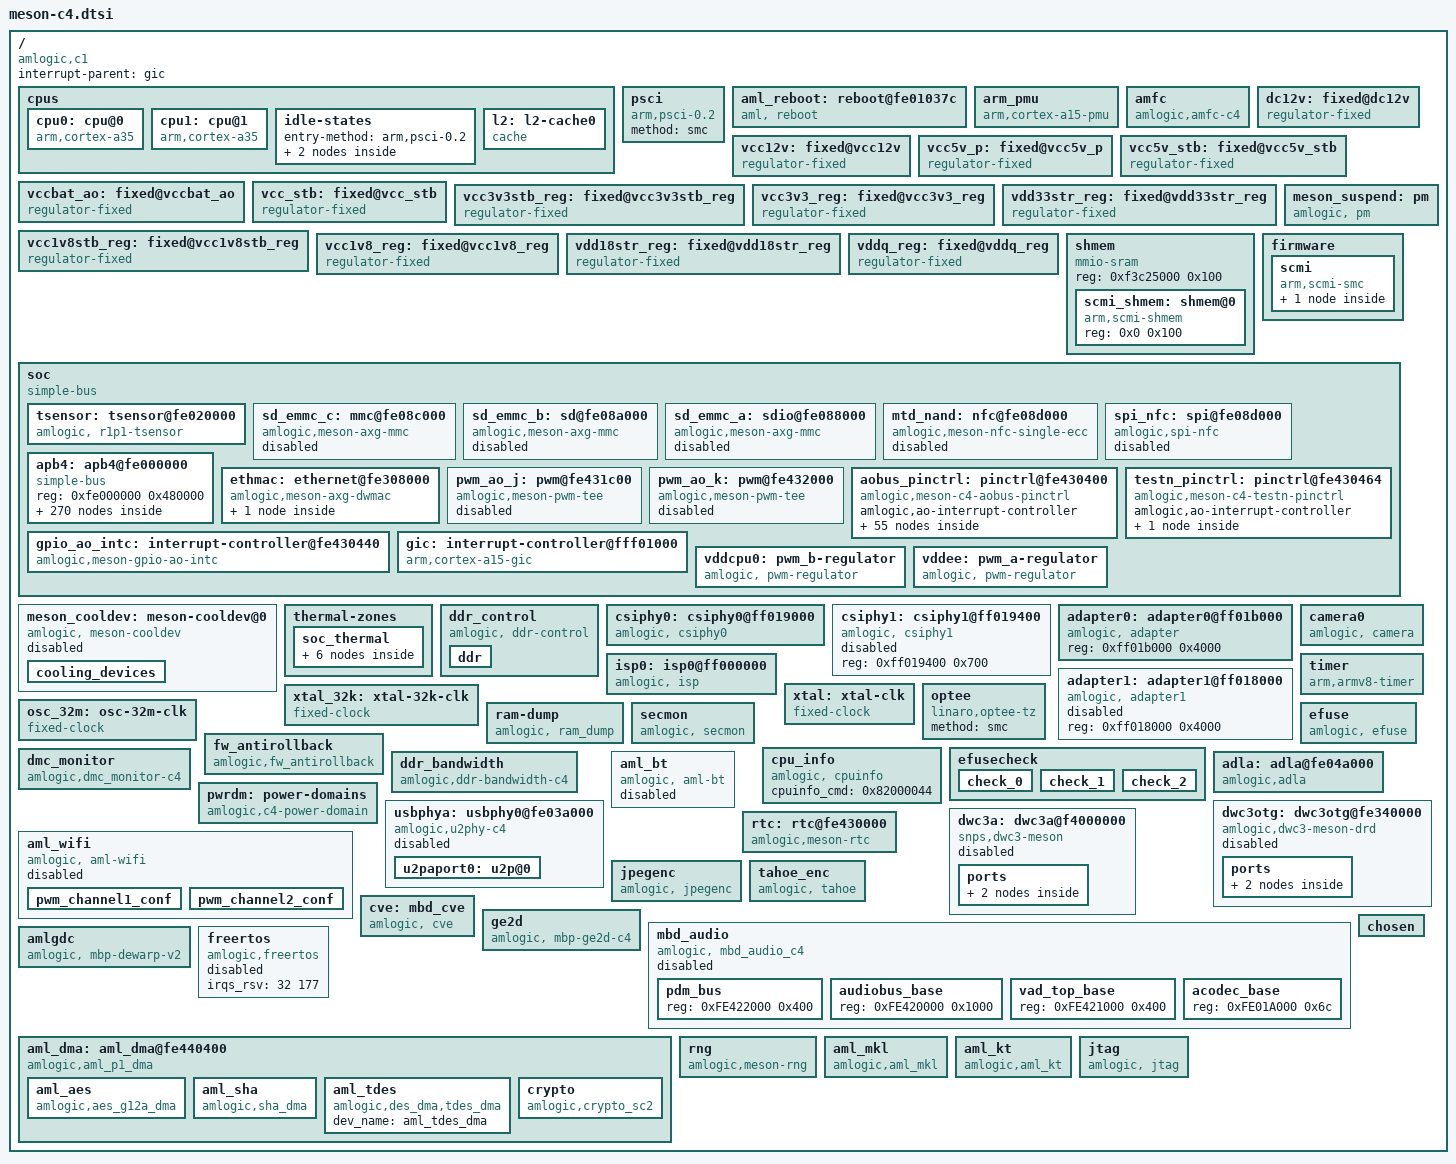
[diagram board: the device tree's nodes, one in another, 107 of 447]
// SPDX-License-Identifier: (GPL-2.0+ OR MIT)
/*
 * Copyright (c) 2019 Amlogic, Inc. All rights reserved.
 */

#include <dt-bindings/interrupt-controller/irq.h>
#include <dt-bindings/interrupt-controller/arm-gic.h>
#include <dt-bindings/clock/amlogic,c4-clkc.h>
#include <dt-bindings/clock/amlogic,c4-scmi-clks.h>
#include <dt-bindings/gpio/gpio.h>
#include <dt-bindings/gpio/meson-c4-gpio.h>
#include <dt-bindings/pwm/pwm.h>
#include <dt-bindings/pwm/meson.h>
#include <dt-bindings/reset/amlogic,meson-c4-reset.h>
#include <dt-bindings/input/input.h>
#include <dt-bindings/input/meson_ir.h>
#include <dt-bindings/iio/adc/amlogic-saradc.h>
#include "meson-ir-map.dtsi"
#include <dt-bindings/power/c4-pd.h>
#include <dt-bindings/mailbox/amlogic,mbox.h>
#include <dt-bindings/thermal/thermal.h>
#include <dt-bindings/thermal/ddr-params.h>
#include <dt-bindings/power/meson-pm.h>

/ {
	compatible = "amlogic,c1";

	interrupt-parent = <&gic>;
	#address-cells = <1>;
	#size-cells = <1>;

	cpus {
		#address-cells = <1>;
		#size-cells = <0>;

		cpu0: cpu@0 {
			device_type = "cpu";
			compatible = "arm,cortex-a35";
			reg = <0x0>;
			enable-method = "psci";
			cpu-idle-states = <&CPU_SLEEP_0>;
			next-level-cache = <&l2>;
			#cooling-cells = <2>;
			dynamic-power-coefficient = <70>;
		};

		cpu1: cpu@1 {
			device_type = "cpu";
			compatible = "arm,cortex-a35";
			reg = <0x1>;
			enable-method = "psci";
			cpu-idle-states = <&CPU_SLEEP_0>;
			next-level-cache = <&l2>;
			#cooling-cells = <2>;
			dynamic-power-coefficient = <70>;
		};
		idle-states {
			entry-method = "arm,psci-0.2";
			CPU_SLEEP_0: cpu-sleep-0 {
					compatible = "arm,idle-state";
					arm,psci-suspend-param = <0x0010000>;
					local-timer-stop;
					entry-latency-us = <3000>;
					exit-latency-us = <3000>;
					min-residency-us = <8000>;
			};
			SYSTEM_SLEEP_0: system-sleep-0 {
					compatible = "arm,idle-state";
					arm,psci-suspend-param = <0x0000000>;
					entry-latency-us = <0x3fffffff>;
					exit-latency-us = <0x40000000>;
					min-residency-us = <0xffffffff>;
			};
		};

		l2: l2-cache0 {
			compatible = "cache";
		};
	};

	psci {
		compatible = "arm,psci-0.2";
		method = "smc";
	};

	aml_reboot: reboot@fe01037c {
		compatible = "aml, reboot";
		sys_reset = <0x84000009>;
		sys_poweroff = <0x84000008>;
		extend_reboot_reason; /* Support up to 128 reboot reasons*/
		reg = <0xfe01037c 0x4>; /* SEC_AO_SEC_SD_CFG15 */
		status = "okay";
	};

	arm_pmu {
		compatible = "arm,cortex-a15-pmu";
		/* clusterb-enabled; */
		private-interrupts;
		interrupts = <GIC_SPI 233 IRQ_TYPE_LEVEL_HIGH>,
			     <GIC_SPI 234 IRQ_TYPE_LEVEL_HIGH>;
	};

	amfc {
		compatible = "amlogic,amfc-c4";
		status = "okay";
		/* registers and clk */
		reg = <0xfe024000 0x200
		       0xfe000000 0x400>;
		interrupts = <0 90 IRQ_TYPE_EDGE_RISING
			      0 91 IRQ_TYPE_EDGE_RISING>;
		power-domains = <&pwrdm PDID_C4_AMFC>;
		interrupt-names = "amfc0", "amfc1";
		clocks = <&clkc CLKID_AMFC>;
		assigned-clocks = <&clkc CLKID_AMFC>;
		assigned-clock-rates = <666666666>;
	};

	dc12v: fixed@dc12v {
		compatible = "regulator-fixed";
		regulator-name = "DC12V";
		regulator-min-microvolt = <12000000>;
		regulator-max-microvolt = <12000000>;
		regulator-boot-on;
		regulator-always-on;
	};

	vcc12v: fixed@vcc12v {
		compatible = "regulator-fixed";
		vin-supply = <&dc12v>;
		regulator-name = "VCC12V";
		regulator-min-microvolt = <12000000>;
		regulator-max-microvolt = <12000000>;
		regulator-boot-on;
		regulator-always-on;
	};

	vcc5v_p: fixed@vcc5v_p {
		compatible = "regulator-fixed";
		vin-supply = <&dc12v>;
		regulator-name = "VCC5V_P";
		regulator-min-microvolt = <5000000>;
		regulator-max-microvolt = <5000000>;
		regulator-boot-on;
		regulator-always-on;
	};

	vcc5v_stb: fixed@vcc5v_stb {
		compatible = "regulator-fixed";
		vin-supply = <&dc12v>;
		regulator-name = "VCC5V_STB";
		regulator-min-microvolt = <5000000>;
		regulator-max-microvolt = <5000000>;
		regulator-boot-on;
		regulator-always-on;
	};

	vccbat_ao: fixed@vccbat_ao {
		compatible = "regulator-fixed";
		vin-supply = <&vcc5v_stb>;
		regulator-name = "VCCBAT_AO";
		regulator-min-microvolt = <3300000>;
		regulator-max-microvolt = <3300000>;
		regulator-boot-on;
		regulator-always-on;
	};

	vcc_stb: fixed@vcc_stb {
		compatible = "regulator-fixed";
		vin-supply = <&vccbat_ao>;
		regulator-name = "VCC_STB";
		regulator-min-microvolt = <3300000>;
		regulator-max-microvolt = <3300000>;
		regulator-boot-on;
		regulator-always-on;
	};

	vcc3v3stb_reg: fixed@vcc3v3stb_reg{
		compatible = "regulator-fixed";
		vin-supply = <&vcc_stb>;
		regulator-name = "VCC3V3STB";
		regulator-min-microvolt = <3300000>;
		regulator-max-microvolt = <3300000>;
		regulator-boot-on;
		regulator-always-on;
	};

	vcc3v3_reg: fixed@vcc3v3_reg{
		compatible = "regulator-fixed";
		vin-supply = <&vcc3v3stb_reg>;
		regulator-name = "VCC3V3";
		regulator-min-microvolt = <3300000>;
		regulator-max-microvolt = <3300000>;
		regulator-boot-on;
		regulator-always-on;
	};

	vdd33str_reg: fixed@vdd33str_reg{
		compatible = "regulator-fixed";
		vin-supply = <&vcc3v3stb_reg>;
		regulator-name = "VDD33_STR";
		regulator-min-microvolt = <3300000>;
		regulator-max-microvolt = <3300000>;
		pinctrl-names = "default";
		gpio = <&ao_gpio GPIOAO_1 GPIO_ACTIVE_HIGH>;
		startup-delay-us = <7000>;
		enable-active-high;
		regulator-boot-on;
		regulator-always-on;
	};

	vcc1v8stb_reg: fixed@vcc1v8stb_reg{
		compatible = "regulator-fixed";
		vin-supply = <&vcc_stb>;
		regulator-name = "VCC1V8STB";
		regulator-min-microvolt = <1800000>;
		regulator-max-microvolt = <1800000>;
		regulator-boot-on;
		regulator-always-on;
	};

	vcc1v8_reg: fixed@vcc1v8_reg{
		compatible = "regulator-fixed";
		vin-supply = <&vcc1v8stb_reg>;
		regulator-name = "VCC1V8";
		regulator-min-microvolt = <1800000>;
		regulator-max-microvolt = <1800000>;
		regulator-boot-on;
		regulator-always-on;
	};

	vdd18str_reg: fixed@vdd18str_reg{
		compatible = "regulator-fixed";
		vin-supply = <&vcc1v8stb_reg>;
		regulator-name = "VDD18_STR";
		regulator-min-microvolt = <1800000>;
		regulator-max-microvolt = <1800000>;
		pinctrl-names = "default";
		gpio = <&ao_gpio GPIOAO_1 GPIO_ACTIVE_HIGH>;
		startup-delay-us = <7000>;
		enable-active-high;
		regulator-boot-on;
		regulator-always-on;
	};

	vddq_reg: fixed@vddq_reg {
		compatible = "regulator-fixed";
		vin-supply = <&vcc_stb>;
		regulator-name = "VDDQ";
		regulator-min-microvolt = <1200000>;
		regulator-max-microvolt = <1200000>;
		pinctrl-names = "default";
		gpio = <&ao_gpio GPIOAO_1 GPIO_ACTIVE_HIGH>;
		startup-delay-us = <7000>;
		enable-active-high;
		regulator-boot-on;
		regulator-always-on;
	};

	meson_suspend:pm {
		compatible = "amlogic, pm";
		status = "okay";
		device_name = "aml_pm";
		extend_resume_reason;
		reg = <0xfe010288 0x4>, /*SYSCTRL_STATUS_REG2*/
			<0xfe43245c 0x4>; /*SYSCTRL_STICKY_REG7*/
		deep_mode = <SYSTEM_SUSPEND_EE_PWR_DOWN>;
		/*deep_mode supports custom configuration */
		// deep_mode = <(DEFINE(SENSOR, OFF) | DEFINE(LCD, ON) |DEFINE(DDR, SELFREFRESH))>;
	};

	shmem {
		compatible = "mmio-sram";
		reg = <0xf3c25000 0x100>;
		#address-cells = <1>;
		#size-cells = <1>;
		ranges = <0x0 0xf3c25000 0x100>;

		scmi_shmem: shmem@0 {
			compatible = "arm,scmi-shmem";
			reg = <0x0 0x100>;
		};
	};

	firmware {
		scmi: scmi {
			compatible = "arm,scmi-smc";
			arm,smc-id = <0x820000C1>;
			shmem = <&scmi_shmem>;
			#address-cells = <1>;
			#size-cells = <0>;

			scmi_clk: protocol@14 {
				reg = <0x14>;
				#clock-cells = <1>;
			};
		};
	};

	soc {
		compatible = "simple-bus";
		#address-cells = <1>;
		#size-cells = <1>;
		ranges;

		tsensor: tsensor@fe020000 {
			compatible = "amlogic, r1p1-tsensor";
			status = "okay";
			reg = <0xfe020000 0x50>;
			tsensor_id = <1>;
			cal_type = <0x11>;
			cal_coeff = <324 424 3159 9411>;
			rtemp = <110000>;
			interrupts = <GIC_SPI 30 IRQ_TYPE_LEVEL_HIGH>;
			clocks = <&clkc CLKID_TS>;
			clock-names = "ts_comp";
			#thermal-sensor-cells = <1>;
			reset-names = "ts_rst";
			resets = <&reset RESET_TS_PLL>;
		};

		sd_emmc_c: mmc@fe08c000 {
			compatible = "amlogic,meson-axg-mmc";
			reg = <0xfe08c000 0x800>,
			      <0xfe00016c 0x4>,
			      <0xfe004000 0x4>;
			interrupts = <GIC_SPI 178 IRQ_TYPE_EDGE_RISING>;
			status = "disabled";
			clocks = <&clkc CLKID_SYS_SD_EMMC_C>,
				 <&clkc CLKID_SD_EMMC_C_MUX>,
				 <&clkc CLKID_SD_EMMC_C>,
				 <&scmi_clk CLKID_OSC>,
				 <&clkc CLKID_GP0_PLL>;
			clock-names = "core", "mux0", "mux1", "clkin0", "clkin1";
			card_type = <1>;
			mmc_debug_flag;
			src_clk_rate = <1152000000>;
			tx_delay = <0x11>;
			full-pwr-cycle;
			no-sd;
			no-sdio;
			// resets = <&reset RESET_SD_EMMC_C>;
		};

		sd_emmc_b: sd@fe08a000 {
			compatible = "amlogic,meson-axg-mmc";
			reg = <0xfe08a000 0x800>,
			      <0xfe000168 0x4>,
			      <0xfe004024 0x4>;
			interrupts = <GIC_SPI 177 IRQ_TYPE_EDGE_RISING>;
			status = "disabled";
			clocks = <&clkc CLKID_SYS_SD_EMMC_B>,
				 <&clkc CLKID_SD_EMMC_B_MUX>,
				 <&clkc CLKID_SD_EMMC_B>,
				 <&scmi_clk CLKID_OSC>,
				 <&clkc CLKID_FCLK_DIV2>;
			clock-names = "core", "mux0", "mux1",
					"clkin0", "clkin1";
			card_type = <5>;
			mmc_debug_flag;
			no-mmc;
			no-sdio;
			// resets = <&reset RESET_SD_EMMC_B>;
		};

		sd_emmc_a: sdio@fe088000 {
			compatible = "amlogic,meson-axg-mmc";
			reg = <0xfe088000 0x800>,
			      <0xfe000168 0x4>,
			      <0xfe00400c 0x4>;
			status = "disabled";
			interrupts = <GIC_SPI 176 IRQ_TYPE_EDGE_RISING>;
			clocks = <&clkc CLKID_SYS_SD_EMMC_A>,
				<&clkc CLKID_SD_EMMC_A_MUX>,
				<&clkc CLKID_SD_EMMC_A>,
				<&scmi_clk CLKID_OSC>,
				<&clkc CLKID_FCLK_DIV2>;
				clock-names = "core", "mux0", "mux1", "clkin0", "clkin1";
			card_type = <3>;
			mmc_debug_flag;
			auto-clock-sdio;
			cap-sdio-irq;
			keep-power-in-suspend;
			no-mmc;
			no-sd;
			// resets = <&reset RESET_SD_EMMC_A>;
		};

		mtd_nand: nfc@fe08d000 {
			compatible = "amlogic,meson-nfc-single-ecc";
			status = "disabled";
			reg = <0xfe08d000 0x200>;
			interrupts = <GIC_SPI 87 IRQ_TYPE_EDGE_RISING>;

			clocks = <&clkc CLKID_SYS_SD_EMMC_C>,
					 <&clkc CLKID_FCLK_DIV2>;
			clock-names = "gate", "fdiv2pll";
			nand_clk_ctrl = <0xfe08c000>;
			//power-domains = <&pwrdm PDID_C3_EMMC>;
		};

		spi_nfc: spi@fe08d000 {
			compatible = "amlogic,spi-nfc";
			status = "disabled";
			reg = <0xfe08d000 0x200>,
				  <0xfe08c000 0xc>,
				  <0xfe010180 0x4>;
			clocks = <&clkc CLKID_SYS_SD_EMMC_C>,
					<&clkc CLKID_FCLK_DIV2>;
			clock-names = "gate", "fdiv2pll";
			nand_clk_ctrl = <0xfe08c000>;
			#address-cells = <1>;
			#size-cells = <0>;
		};

		apb4: apb4@fe000000 {
			compatible = "simple-bus";
			reg = <0xfe000000 0x480000>;
			#address-cells = <1>;
			#size-cells = <1>;
			ranges = <0x0 0xfe000000 0x480000>;

			clkc: clock-controller@0 {
				compatible = "amlogic,c4-clkc";
				#clock-cells = <1>;
				reg = <0x0    0x228>,
				      <0x8000 0x194>;
				reg-names = "basic", "pll";
				clocks = <&xtal>,
					 <&scmi_clk CLKID_OSC>,
					 <&scmi_clk CLKID_SYS_CLK>,
					 <&scmi_clk CLKID_AXI_CLK>,
					 <&scmi_clk CLKID_FIXED_PLL>;
				clock-names = "xtal",
					      "oscin",
					      "sys_clk",
					      "axi_clk",
					      "fixed_pll";
				status = "okay";
			};

			reset: reset-controller@2000 {
				compatible = "amlogic,meson-sc2-reset";
				reg = <0x2000 0x98>;
				#reset-cells = <1>;
			};

			periphs_pinctrl: pinctrl@4000 {
				compatible = "amlogic,meson-c4-periphs-pinctrl";
				#address-cells = <1>;
				#size-cells = <1>;
				ranges;

				gpio: bank@4000 {
					reg = <0x4000 0x004c>,
					      <0x40c0 0x0240>;
					reg-names = "mux", "gpio";
					gpio-controller;
					#gpio-cells = <2>;
					gpio-ranges = <&periphs_pinctrl 0 0 55>;
				};
			};

			gpio_intc: interrupt-controller@4080 {
				compatible = "amlogic,meson-gpio-intc",
					      "amlogic,meson-c4-gpio-intc";
				reg = <0x4080 0x20>;
				interrupt-controller;
				#interrupt-cells = <2>;
				amlogic,channel-interrupts =
							<10 11 12 13 14 15 16 17 18 19 20 21>;
			};

			analog_pinctrl: pinctrl@43a0 {
				compatible = "amlogic,meson-c3-analog-pinctrl";
				#address-cells = <1>;
				#size-cells = <1>;
				ranges;

				gpio_analog: bank@43a0 {
					reg = <0x404c 0x008>,
					      <0x438c 0x030>;
					reg-names = "mux", "gpio";
					gpio-controller;
					#gpio-cells = <2>;
					gpio-ranges = <&analog_pinctrl 0 0 14>;
				};
			};

			meson_clk_msr@48000 {
				compatible = "amlogic,c4-clk-measure";
				reg = <0x48000 0x1c>;
			};

			spicc0: spi@50000 {
				compatible = "amlogic,meson-t6x-spicc-v2";
				reg = <0x50000 0x100>;
				interrupts = <GIC_SPI 183 IRQ_TYPE_LEVEL_HIGH>;
				clocks = <&clkc CLKID_SYS_SPICC>,
					 <&clkc CLKID_SPICC0>;
				clock-names = "sys", "spi";
				#address-cells = <1>;
				#size-cells = <0>;
				status = "disabled";
			};

			spicc1: spi@50100 {
				compatible = "amlogic,meson-t6x-spicc-v2";
				reg = <0x50100 0x100>;
				interrupts = <GIC_SPI 184 IRQ_TYPE_LEVEL_HIGH>;
				clocks = <&clkc CLKID_SYS_SPICC>,
					 <&clkc CLKID_SPICC1>;
				clock-names = "sys", "spi";
				#address-cells = <1>;
				#size-cells = <0>;
				status = "disabled";
			};

			i2c0: i2c@66000 {
				compatible = "amlogic,meson-i2c-v2";
				reg = <0x66000 0x3c>;
				interrupts = <GIC_SPI 160 IRQ_TYPE_EDGE_RISING>;
				#address-cells = <1>;
				#size-cells = <0>;
				clocks = <&clkc CLKID_SYS_I2C_M_A>;
				status = "disabled";
			};

			i2c1: i2c@66400 {
				compatible = "amlogic,meson-i2c-v2";
				reg = <0x66400 0x3c>;
				interrupts = <GIC_SPI 161 IRQ_TYPE_EDGE_RISING>;
				#address-cells = <1>;
				#size-cells = <0>;
				clocks = <&clkc CLKID_SYS_I2C_M_B>;
				status = "disabled";
			};

			i2c2: i2c@66800 {
				compatible = "amlogic,meson-i2c-v2";
				reg = <0x66800 0x3c>;
				interrupts = <GIC_SPI 162 IRQ_TYPE_EDGE_RISING>;
				#address-cells = <1>;
				#size-cells = <0>;
				clocks = <&clkc CLKID_SYS_I2C_M_C>;
				status = "disabled";
			};

			i2c3: i2c@66c00 {
				compatible = "amlogic,meson-i2c-v2";
				reg = <0x66c00 0x3c>;
				interrupts = <GIC_SPI 163 IRQ_TYPE_EDGE_RISING>;
				#address-cells = <1>;
				#size-cells = <0>;
				clocks = <&clkc CLKID_SYS_I2C_M_D>;
				status = "disabled";
			};

			i2c4: i2c@64000 {
				compatible = "amlogic,meson-i2c-v2";
				reg = <0x68000 0x3c>;
				interrupts = <GIC_SPI 166 IRQ_TYPE_EDGE_RISING>;
				#address-cells = <1>;
				#size-cells = <0>;
				clocks = <&clkc CLKID_SYS_I2C_S_A>;
				status = "disabled";
			};

			pwm_a: pwm@58000 {
				compatible = "amlogic,meson-pwm-tee";
				reg = <0x58000 0x24>;
				#pwm-cells = <3>;
				clocks = <&scmi_clk CLKID_PWM_A>;
				clock-names = "clkin0";
				tee_id = <0>;
				status = "okay";
			};

			pwm_b: pwm@58200 {
				compatible = "amlogic,meson-pwm-tee";
				reg = <0x58200 0x24>;
				#pwm-cells = <3>;
				clocks = <&scmi_clk CLKID_PWM_B>;
				clock-names = "clkin0";
				tee_id = <1>;
				status = "okay";
			};

			pwm_c: pwm@58400 {
				compatible = "amlogic,meson-pwm-tee";
				reg = <0x58400 0x24>;
				#pwm-cells = <3>;
				clocks = <&clkc CLKID_PWM_C>;
				clock-names = "clkin0";
				tee_id = <2>;
				status = "disabled";
			};

			pwm_d: pwm@58600 {
				compatible = "amlogic,meson-pwm-tee";
				reg = <0x58600 0x24>;
				#pwm-cells = <3>;
				clocks = <&clkc CLKID_PWM_D>;
				clock-names = "clkin0";
				tee_id = <3>;
				status = "disabled";
			};

			pwm_e: pwm@58800 {
				compatible = "amlogic,meson-pwm-tee";
				reg = <0x58800 0x24>;
				#pwm-cells = <3>;
				clocks = <&clkc CLKID_PWM_E>;
				clock-names = "clkin0";
				tee_id = <4>;
				status = "disabled";
			};

			pwm_f: pwm@58a00 {
				compatible = "amlogic,meson-pwm-tee";
				reg = <0x58a00 0x24>;
				#pwm-cells = <3>;
				clocks = <&clkc CLKID_PWM_F>;
				clock-names = "clkin0";
				tee_id = <5>;
				status = "disabled";
			};

			pwm_g: pwm@58c00 {
				compatible = "amlogic,meson-pwm-tee";
				reg = <0x58c00 0x24>;
				#pwm-cells = <3>;
				clocks = <&clkc CLKID_PWM_G>;
				clock-names = "clkin0";
				tee_id = <6>;
				status = "disabled";
			};

			pwm_h: pwm@58e00 {
				compatible = "amlogic,meson-pwm-tee";
				reg = <0x58e00 0x24>;
				#pwm-cells = <3>;
				clocks = <&clkc CLKID_PWM_H>;
				clock-names = "clkin0";
				tee_id = <7>;
				status = "disabled";
			};

			pwm_i: pwm@59000 {
				compatible = "amlogic,meson-pwm-tee";
				reg = <0x59000 0x24>;
				#pwm-cells = <3>;
				clocks = <&clkc CLKID_PWM_I>;
				clock-names = "clkin0";
				tee_id = <8>;
				status = "disabled";
			};

			pwm_j: pwm@59200 {
				compatible = "amlogic,meson-pwm-tee";
				reg = <0x59200 0x24>;
				#pwm-cells = <3>;
				clocks = <&clkc CLKID_PWM_J>;
				clock-names = "clkin0";
				tee_id = <9>;
				status = "disabled";
			};

			pwm_k: pwm@59400 {
				compatible = "amlogic,meson-pwm-tee";
				reg = <0x59400 0x24>;
				#pwm-cells = <3>;
				clocks = <&clkc CLKID_PWM_K>;
				clock-names = "clkin0";
				tee_id = <10>;
				status = "disabled";
			};

			pwm_l: pwm@59600 {
				compatible = "amlogic,meson-pwm-tee";
				reg = <0x59600 0x24>;
				#pwm-cells = <3>;
				clocks = <&clkc CLKID_PWM_L>;
				clock-names = "clkin0";
				tee_id = <11>;
				status = "disabled";
			};

			pwm_m: pwm@59800 {
				compatible = "amlogic,meson-pwm-tee";
				reg = <0x59800 0x24>;
				#pwm-cells = <3>;
				clocks = <&clkc CLKID_PWM_M>;
				clock-names = "clkin0";
				tee_id = <12>;
				status = "disabled";
			};

			pwm_n: pwm@59a00 {
				compatible = "amlogic,meson-pwm-tee";
				reg = <0x59a00 0x24>;
				#pwm-cells = <3>;
				clocks = <&clkc CLKID_PWM_N>;
				clock-names = "clkin0";
				tee_id = <13>;
				status = "disabled";
			};

			uart_A: serial@78000 {
				compatible = "amlogic,meson-uart";
				reg = <0x78000 0x18>;
				interrupts = <GIC_SPI 168 IRQ_TYPE_EDGE_RISING>;
				status = "disabled";
				clocks = <&xtal
					&clkc CLKID_SYS_UART_A>;
				clock-names = "clk_uart", "clk_gate";
				xtal_tick_en = <2>;
				fifosize = < 64 >;
				pinctrl-names = "default";
				pinctrl-0 = <&a_uart_pins1>;
			};

			uart_B: serial@7a000 {
				compatible = "amlogic,meson-uart";
				reg = <0x7a000 0x18>;
				interrupts = <GIC_SPI 169 IRQ_TYPE_EDGE_RISING>;
				status = "okay";
				clocks = <&xtal>;
				clock-names = "clk_uart";
				xtal_tick_en = <2>;
				fifosize = < 64 >;
				//pinctrl-names = "default";
				/*pinctrl-0 = <&ao_uart_pins>;*/
				support-sysrq = <1>;
			};

			uart_C: serial@7c000 {
				compatible = "amlogic,meson-uart";
				reg = <0x7c000 0x18>;
				interrupts = <GIC_SPI 170 IRQ_TYPE_EDGE_RISING>;
				status = "disabled";
				clocks = <&xtal
					&clkc CLKID_SYS_UART_C>;
				clock-names = "clk_uart", "clk_gate";
				fifosize = < 64 >;
				pinctrl-names = "default";
				pinctrl-0 = <&c_uart_pins5>;
			};

			uart_D: serial@7e000 {
				compatible = "amlogic,meson-uart";
				reg = <0x7e000 0x18>;
				interrupts = <GIC_SPI 171 IRQ_TYPE_EDGE_RISING>;
				status = "disabled";
				clocks = <&xtal
					&clkc CLKID_SYS_UART_D>;
				clock-names = "clk_uart", "clk_gate";
				fifosize = < 64 >;
				pinctrl-names = "default";
				pinctrl-0 = <&d_uart_pins1>;
			};

			uart_E: serial@80000 {
				compatible = "amlogic,meson-uart";
				reg = <0x80000 0x18>;
				interrupts = <GIC_SPI 172 IRQ_TYPE_EDGE_RISING>;
				status = "disabled";
				clocks = <&xtal
					&clkc CLKID_SYS_UART_E>;
				clock-names = "clk_uart", "clk_gate";
				fifosize = < 64 >;
				pinctrl-names = "default";
				pinctrl-0 = <&e_uart_pins1>;
			};

			uart_F: serial@82000 {
				compatible = "amlogic,meson-uart";
				reg = <0x82000 0x18>;
				interrupts = <GIC_SPI 173 IRQ_TYPE_EDGE_RISING>;
				status = "disabled";
				clocks = <&xtal
					&clkc CLKID_SYS_UART_F>;
				clock-names = "clk_uart", "clk_gate";
				fifosize = < 64 >;
				pinctrl-names = "default";
				pinctrl-0 = <&f_uart_pins1>;
			};

			watchdog@2100 {
				compatible = "amlogic,meson-a4-wdt";
				status = "okay";
				/* 0:userspace, 1:kernel */
				amlogic,feed_watchdog_mode = <1>;
				reg = <0x2100 0x10>, <0x2124 0x04>;
				interrupts = <GIC_SPI 9 IRQ_TYPE_EDGE_RISING>;
				clocks = <&scmi_clk CLKID_OSC>;
			};

			saradc: adc@26000 {
				compatible = "amlogic,meson-s7-saradc",
					     "amlogic,meson-saradc";
				reg = <0x26000 0xf0>;
				#io-channel-cells = <1>;
				interrupts = <GIC_SPI 181 IRQ_TYPE_EDGE_RISING>;
				clocks = <&scmi_clk CLKID_OSC>,
					 <&clkc CLKID_SYS_SAR_ADC>,
					 <&clkc CLKID_SAR_ADC>,
					 <&clkc CLKID_SAR_ADC_MUX>;
				clock-names = "clkin", "core", "adc_clk", "adc_sel";
				status = "disabled";
			};

			eth_phy: mdio-multiplexer@300000 {
				compatible = "amlogic,g12a-mdio-mux";
				reg = <0x300000 0x198>;

				clocks = <&clkc CLKID_SYS_ETH_PHY>,
					<&xtal>,
					<&clkc CLKID_FCLK_50M>;
				clock-names = "pclk", "clkin0", "clkin1";
				mdio-parent-bus = <&mdio0>;
				#address-cells = <1>;
				#size-cells = <0>;
				phy_pll_mode = <4>;
				phy_mode = <8>;
				ephy_clk_gate = <0x7>;
				ephy_eee_support = <1>;
				tx_amp_src = <0xFE010330>;
				status = "disabled";

				ext_mdio: mdio@0 {
					reg = <0>;
					#address-cells = <1>;
					#size-cells = <0>;
				};

				int_mdio: mdio@1 {
					reg = <1>;
					#address-cells = <1>;
					#size-cells = <0>;

					internal_ephy: ethernet_phy@8 {
						compatible = "ethernet-phy-id0180.3301",
							     "ethernet-phy-ieee802.3-c22";
						interrupts = <GIC_SPI 75 IRQ_TYPE_LEVEL_HIGH>;
						reg = <8>;
						max-speed = <100>;
					};
				};
			};

			ao_clkc: clock-controller@431000 {
				compatible = "amlogic,c4-aoclkc";
				reg = <0x431000 0x20>;
				reg-names = "basic";
				#clock-cells = <1>;
				clocks = <&xtal>,
					 <&xtal_32k>,
					 <&osc_32m>,
					<&scmi_clk CLKID_SYS_CLK>;
				clock-names = "xtal",
					      "xtal_32k",
					      "osc_32m",
					      "sys_clk";
			};
		};

		ethmac: ethernet@fe308000 {
			compatible = "amlogic,meson-axg-dwmac",
				     "snps,dwmac-4.00";
			reg = <0xfe308000 0x12ec>,
			      <0xfe304000 0x2c>;
			interrupts = <GIC_SPI 74 IRQ_TYPE_LEVEL_HIGH>;
			interrupt-names = "macirq";
			clocks = <&clkc CLKID_SYS_ETH_PHY>,
				 <&clkc CLKID_FCLK_DIV2>,
				 <&clkc CLKID_FCLK_50M>;
			clock-names = "stmmaceth", "clkin0", "clkin1";
			rx-fifo-depth = <4096>;
			tx-fifo-depth = <2048>;
			/*1:inphy; 2:exphy;*/
			internal_phy = <1>;
			analog_version = <1>;
			suspend-no-vddee;
			/*mboxes = <&mbox_fifo T6X_REE2AO_ETH>;*/

			mdio0: mdio {
				#address-cells = <1>;
				#size-cells = <0>;
				compatible = "snps,dwmac-mdio";
			};
		};

		pwm_ao_j: pwm@fe431c00 {
			compatible = "amlogic,meson-pwm-tee";
			reg = <0xfe431c00 0x24>;
			#pwm-cells = <3>;
			clocks = <&ao_clkc CLKID_AO_PWM_J>;
			clock-names = "clkin0";
			tee_id = <14>;
			status = "disabled";
		};

		pwm_ao_k: pwm@fe432000 {
			compatible = "amlogic,meson-pwm-tee";
			reg = <0xfe432000 0x24>;
			#pwm-cells = <3>;
			clocks = <&ao_clkc CLKID_AO_PWM_K>;
			clock-names = "clkin0";
			tee_id = <15>;
			status = "disabled";
		};

		aobus_pinctrl: pinctrl@fe430400 {
			compatible = "amlogic,meson-c4-aobus-pinctrl";
			#address-cells = <1>;
			#size-cells = <1>;
			ranges;
			amlogic,ao-interrupt-controller;

			ao_gpio: bank@fe430400 {
				reg = <0xfe430400 0x08>,
				      <0xfe430408 0x20>;
				reg-names = "mux", "gpio";
				gpio-controller;
				#gpio-cells = <2>;
				gpio-ranges = <&aobus_pinctrl 0 0 14>;
			};
		};

		testn_pinctrl: pinctrl@fe430464 {
			compatible = "amlogic,meson-c4-testn-pinctrl";
			#address-cells = <1>;
			#size-cells = <1>;
			ranges;
			amlogic,ao-interrupt-controller;

			testn_gpio: bank@fe430464 {
				reg = <0xfe430484 0x04>,
				      <0xfe430464 0x20>;
				reg-names = "mux", "gpio";
				gpio-controller;
				#gpio-cells = <2>;
				gpio-ranges = <&testn_pinctrl 0 0 1>;
			};
		};

		gpio_ao_intc: interrupt-controller@fe430440 {
			compatible = "amlogic,meson-gpio-ao-intc",
					"amlogic,meson-c4-gpio-ao-intc";
			reg = <0xfe430440 0x18>;
			interrupt-controller;
			#interrupt-cells = <2>;
			amlogic,channel-interrupts = <192 193 194 195 196 197 198 199 200>;
		};

		gic: interrupt-controller@fff01000 {
		compatible = "arm,cortex-a15-gic", "arm,cortex-a9-gic";
		#interrupt-cells = <3>;
		#address-cells = <0>;
		interrupt-controller;
		reg = <0xfff01000 0x1000>,
		      <0xfff02000 0x0100>;
		interrupts = <GIC_PPI 9 0xf04>;
		};

		vddcpu0: pwm_b-regulator {
			compatible = "amlogic, pwm-regulator";
			cpu0-supply = <&vcc_stb>;
			pwms = <&pwm_b MESON_PWM_0 1500 0>;
			regulator-name = "vddcpu0";
			regulator-min-microvolt = <690000>;
			regulator-max-microvolt = <1050000>;
			regulator-always-on;
			max-duty-cycle = <1500>;
			amlogic,vsel-step = <3>;
			amlogic,udelay-time = <40 20>; //pwm 1nF
			/* Voltage Duty-Cycle */
			voltage-table = <1050000 0>,
					<1040000 3>,
					<1030000 6>,
					<1020000 8>,
					<1010000 11>,
					<1000000 14>,
					<990000 17>,
					<980000 19>,
					<970000 22>,
					<960000 25>,
					<950000 28>,
					<940000 31>,
					<930000 33>,
					<920000 36>,
					<910000 39>,
					<900000 42>,
					<890000 44>,
					<880000 47>,
					<870000 50>,
					<860000 53>,
					<850000 56>,
					<840000 58>,
					<830000 61>,
					<820000 64>,
					<810000 67>,
					<800000 69>,
					<790000 72>,
					<780000 75>,
					<770000 78>,
					<760000 81>,
					<750000 83>,
					<740000 86>,
					<730000 89>,
					<720000 92>,
					<710000 94>,
					<700000 97>,
					<690000 100>;
			status = "okay";
		};

		vddee: pwm_a-regulator {
			compatible = "amlogic, pwm-regulator";
			vddee-supply = <&vcc_stb>;
			pwms = <&pwm_a MESON_PWM_0 840 0>;
			regulator-name = "vddee";
			regulator-min-microvolt = <700000>;
			regulator-max-microvolt = <900000>;
			regulator-always-on;
			max-duty-cycle = <840>;
			amlogic,vsel-step = <3>;
			amlogic,udelay-time = <40 20>; //pwm 1nF
			/* Voltage Duty-Cycle */
			voltage-table = <900000 0>,
					<890000 5>,
					<880000 10>,
					<870000 15>,
					<860000 20>,
					<850000 25>,
					<840000 30>,
					<830000 35>,
					<820000 40>,
					<810000 45>,
					<800000 50>,
					<790000 55>,
					<780000 60>,
					<770000 65>,
					<760000 70>,
					<750000 75>,
					<740000 80>,
					<730000 85>,
					<720000 90>,
					<710000 95>,
					<700000 100>;
			status = "okay";
		};
	};

	meson_cooldev: meson-cooldev@0 {
		status = "disabled";
		compatible = "amlogic, meson-cooldev";
		cooling_devices {
		};
	};

	/*meson cooling devices end*/
	thermal-zones {
		soc_thermal:soc_thermal {
			polling-delay = <1000>;
			polling-delay-passive = <100>;
			sustainable-power = <272>;
			thermal-sensors = <&tsensor 0>;
			trips {
				pswitch_on: trip-point@0 {
					temperature = <60000>;
					hysteresis = <2000>;
					type = "passive";
				};
				pcontrol: trip-point@1 {
					temperature = <75000>;
					hysteresis = <2000>;
					type = "passive";
				};
				pcritical: trip-point@2 {
					temperature = <105000>;
					hysteresis = <1000>;
					type = "critical";
				};
			};
			cooling-maps {
				cpufreq_cooling_map {
					trip = <&pcontrol>;
					cooling-device = <&cpu0 0 3>;
					contribution = <1024>;
				};
			};
		};
	};

	ddr_control: ddr_control {
		compatible = "amlogic, ddr-control";
		reg = <0xfe0368a8 0x4>;
		reg-names = "freq-addr";
		freq-mask = <0 16>;
		version = "v1";
		status = "okay";
		ddr {
			condition-type = <DDR_THERMAL>;
			zone-name = "soc_thermal";
			caddr = <0xfe0364b4>,
				<0xfe0365b4>;
			caddr-mask = <0 16>,
				     <0 16>;
			cstep-val = <70000 75000 80000 85000 90000>,
				    <95000 100000 105000 110000 115000 120000>;
			caddr-val = <7800 3900>,
				    <6240 3120>,
				    <4875 2438>,
				    <4875 2438>,
				    <3900 1950>,
				    <3120 1560>,
				    <2437 1219>,
				    <1950 975>,
				    <975 488>,
				    <650 325>,
				    <488 244>;
		};
	};

	csiphy0: csiphy0@ff019000 {
		compatible = "amlogic, csiphy0";
		reg = <0xff019000 0x700>;
		//power-domains = <&pwrdm PDID_C3_ISP_TOP>;
		clocks = <&clkc CLKID_CSI_PHY>;
		clock-names = "mipi_phy_clk";
		reg-names = "csi_phy0";
		status = "okay";
	};

	csiphy1: csiphy1@ff019400 {
		compatible = "amlogic, csiphy1";
		reg = <0xff019400 0x700>;
		reg-names = "csi_phy1";
		//clocks = <&clkc CLKID_CSI_PHY>;
		//clock-names = "mipi_phy_clk";
		status = "disabled";
	};

	adapter0: adapter0@ff01b000 {
		compatible = "amlogic, adapter";
		reg = <0xff01b000 0x4000>;
		reg-names = "adapter";
		//interrupts = <0 159 1>;
		status = "okay";
	};

	adapter1: adapter1@ff018000 {
		compatible = "amlogic, adapter1";
		reg = <0xff018000 0x4000>;
		reg-names = "adapter";
		status = "disabled";
	};

	isp0: isp0@ff000000 {
		compatible = "amlogic, isp";
		reg = <0xff000000 0x10100>;
		power-domains = <&pwrdm PDID_C4_MIPI_ISP>,<&pwrdm PDID_C4_OPP>;
		power-domain-names = "isp_pd", "opp_pd";
		clocks = <&clkc CLKID_CSI_PHY>, <&clkc CLKID_ISP>, <&clkc CLKID_DEWARP>;
		clock-names = "mipi_csi_clk", "mipi_isp_clk", "isp_dewarp_clk";
		interrupts = <GIC_SPI 159 IRQ_TYPE_EDGE_RISING>,
			     <GIC_SPI 148 IRQ_TYPE_EDGE_RISING>,
			     <GIC_SPI 149 IRQ_TYPE_EDGE_RISING>,
			     <GIC_SPI 150 IRQ_TYPE_EDGE_RISING>,
			     <GIC_SPI 155 IRQ_TYPE_EDGE_RISING>,
			     <GIC_SPI 156 IRQ_TYPE_EDGE_RISING>;
		interrupt-names = "fe_rst", "fe_done", "be_done",
				  "opp_done", "mipi_top", "intf";
		status = "okay";
	};

	camera0 {
		compatible = "amlogic, camera";
		index = <0>;
		csiphy = <&csiphy0>;
		adapter = <&adapter0>;
		isp = <&isp0>;
		status = "okay";
	};

	timer {
		compatible = "arm,armv8-timer";
		interrupts = <GIC_PPI 13
			(GIC_CPU_MASK_RAW(0xff) | IRQ_TYPE_LEVEL_LOW)>,
			     <GIC_PPI 14
			(GIC_CPU_MASK_RAW(0xff) | IRQ_TYPE_LEVEL_LOW)>,
			     <GIC_PPI 11
			(GIC_CPU_MASK_RAW(0xff) | IRQ_TYPE_LEVEL_LOW)>,
			     <GIC_PPI 10
			(GIC_CPU_MASK_RAW(0xff) | IRQ_TYPE_LEVEL_LOW)>;
	};

	xtal: xtal-clk {
		compatible = "fixed-clock";
		clock-frequency = <24000000>;
		clock-output-names = "xtal";
		#clock-cells = <0>;
	};

	xtal_32k: xtal-32k-clk {
		compatible = "fixed-clock";
		clock-frequency = <32768>;
		clock-output-names = "xtal_32k";
		#clock-cells = <0>;
	};

	osc_32m: osc-32m-clk {
		compatible = "fixed-clock";
		clock-frequency = <32000000>;
		clock-output-names = "osc_32m";
		#clock-cells = <0>;
	};

	optee {
		compatible = "linaro,optee-tz";
		method = "smc";
		status = "okay";
	};

	ram-dump {
		compatible = "amlogic, ram_dump";
		status = "okay";
		reg = <0xFE432458 0x4>;
		reg-names = "SYSCTRL_STICKY_REG6";
		store_device = "data";
	};

	secmon {
		compatible = "amlogic, secmon";
		memory-region = <&secmon_reserved>;
		reserve_mem_size = <0x00110000>;
		in_base_func = <0x82000020>;
		out_base_func = <0x82000021>;
	};

	fw_antirollback: fw_antirollback {
		compatible = "amlogic,fw_antirollback";
		status = "okay";
		fw_arb_cmd = <0x8200006D>;
		sub_check_cmd = <0x200>;
		sub_update_cmd = <0x100>;
	};

	cpu_info {
		compatible = "amlogic, cpuinfo";
		status = "okay";
		cpuinfo_cmd = <0x82000044>;
	};

	efusecheck: efusecheck{
		maincmd = <0x8200003E>;
		checknum = <3>;
		check0 = <&check_0>;
		check1 = <&check_1>;
		check2 = <&check_2>;
		check_0:check_0{
			checkname = "dgpk1";
			subcmd = <0x1000>;
		};
		check_1:check_1{
			checkname = "dgpk2";
			subcmd = <0x1001>;
		};
		check_2:check_2{
			checkname = "aud_id";
			subcmd = <0x1002>;
		};
	};

	efuse: efuse{
		compatible = "amlogic, efuse";
		reg=<0xfe440040 0x4>;
		secureboot_mask = <0x00000c00>;
		read_cmd = <0x82000030>;
		write_cmd = <0x82000031>;
		get_max_cmd = <0x82000033>;
		mem_in_base_cmd = <0x82000020>;
		mem_out_base_cmd = <0x82000021>;
		efuse_pattern_size = <0x400>;
		efuse_obj_cmd_status = <0x1>;
		efuse_cali_item_read = <0x1>;
		check = <&efusecheck>;
		clock-names = "efuse_clk";
		status = "okay";
	};

	ddr_bandwidth {
		compatible = "amlogic,ddr-bandwidth-c4";
		status = "okay";
		reg = <0xfe036000 0x1000
		       0xfe0368a8 0x4>;
		interrupts = <0 78 IRQ_TYPE_EDGE_RISING>;
		interrupt-names = "ddr_bandwidth";
	};

	dmc_monitor {
		compatible = "amlogic,dmc_monitor-c4";
		status = "okay";
		memory-region = <&dmc_reserved>;
		reg_base = <0xfe036000>;
		reg = <0xfe036000 0x400>;
		interrupts = <0 62 IRQ_TYPE_LEVEL_HIGH
			      0 61 IRQ_TYPE_EDGE_RISING>;
	};

	adla: adla@fe04a000 {
		compatible = "amlogic,adla";
		dev_name = "adla";
		status = "okay";
		reg = <0xfe04a000 0x2000
			0xf3C05000 0x1E000
			>;
		reg-names = "adla_reg\0adla_sram";
		interrupt-names = "adla";
		interrupts = <GIC_SPI 128 IRQ_TYPE_LEVEL_HIGH>;
		clocks = <&clkc CLKID_NNA>;
		clock-names = "adla_core_clk";
		power-domains=<&pwrdm PDID_C4_NNA>;
		nn_hw_version="r0p1";
		adla_core_clk_rate = <800000000>;
		adla_smc_cmd = <0x820000b2>;
		//memory-region = <&nna_cma_reserved>;
	};
	pwrdm: power-domains {
		compatible = "amlogic,c4-power-domain";
		#power-domain-cells = <1>;
		status = "okay";
	};

	usbphya: usbphy0@fe03a000 {
		compatible = "amlogic,u2phy-c4";
		#address-cells = <1>;
		#size-cells = <1>;
		//ranges = <0 0 0 0x1000>;
		status = "disabled";
		u2paport0: u2p@0 {
			#phy-cells = <0>;
			port-speed = <0x0>; /* 0~2: HS HSP SS */
			reg = <0xfe03a000 0x100
					0xfe002000 0x100
					0xfe010330 0x4
					0xfe03c000 0x60>;
			reset-level = <0x40>;
			phy-reset-level-bits = <8>;
			phy-apb-reset-bit = <7>;
			phy-comb-reset-bit = <4>;
			usb-reset-bit = <10>;
			pll-settings = <0x0
							0x0
							0x0
							0x0
							0x7>;
			clocks = <&clkc CLKID_SYS_USB>;
			clock-names = "sys_usb";
			interrupts = <GIC_SPI 129 IRQ_TYPE_EDGE_RISING>;
			power-domains = <&pwrdm PDID_C4_U2DRD>;
		};
	};

	dwc3otg: dwc3otg@fe340000{
		status = "disable";
		compatible = "amlogic,dwc3-meson-drd";
		reg = <0xfe03a000 0x100>;
		phys = <&u2paport0>;
		phy-names = "usb2-phy";
		interrupts = <GIC_SPI 129 IRQ_TYPE_EDGE_RISING>;
		ports {
			#address-cells = <1>;
			#size-cells = <0>;
			port@0 {
				reg = <0>;
				usb_otg_ep: endpoint {
					remote-endpoint = <&usb2_role_switch>;
				};
			};
		};

	};

	dwc3a: dwc3a@f4000000 {
		status = "disable";
		compatible = "snps,dwc3-meson";
		maximum-speed = "high-speed";
		dr_mode = "otg"; /*using role control mode, this must be otg*/
		//dr_mode = "peripheral";
		phy_type = "utmi";
		reg = <0xf4000000 0x10000>;
		interrupts = <GIC_SPI 130 IRQ_TYPE_LEVEL_HIGH>;
		interrupt-names = "dwc_usb3";
		clocks = <&clkc CLKID_SYS_USB>, <&xtal>, <&xtal>;
		clock-names = "bus_early", "ref", "suspend";
		phys = <&u2paport0>;
		phy-names = "usb2-phy";
		power-domains = <&pwrdm PDID_C4_U2DRD>;
		resets = <&reset RESET_U2DRD>;
		snps,usb2-lpm-disable;
		//snps,usb3_lpm_capable;
		snps,usb2-gadget-lpm-disable;
		snps,has-lpm-erratum;
		/* better try */
		//snps,rx_detect_poll_quirk;
		snps,dis_u3_susphy_quirk;
		snps,dis_u2_susphy_quirk;
		snps,dis_enblslpm_quirk;
		/* why we do this? dwc3_ref_clk_period() must enable GFLADJ_REFCLK_LPM_SEL */
		//snps,dis-u2-freeclk-exists-quirk;
		//snps,gfladj-refclk-lpm-sel-quirk;
		/* need post-silicon test. */
		//snps,quirk-frame-length-adjustment;
		snps,rx-thr-num-pkt = <2>;
		snps,rx-max-burst = <16>;
		snps,tx-thr-num-pkt = <2>;
		snps,tx-max-burst = <16>;
		tx-fifo-resize;
		tx-fifo-max-num = <3>;
		snps,incr-burst-type-adjustment = <4>;
		usb-role-switch;

		ports {
			#address-cells = <1>;
			#size-cells = <0>;
			port@0 {
				reg = <0>;
				usb2_role_switch: endpoint {
					remote-endpoint = <&usb_otg_ep>;
				};
			};
		};
	};

	aml_bt: aml_bt {
		compatible = "amlogic, aml-bt";
		status = "disabled";
		//reset-gpios = <&gpio       GPIOX_17       GPIO_ACTIVE_HIGH>;
	};

	aml_wifi: aml_wifi {
		compatible = "amlogic, aml-wifi";
		status = "disabled";
		wifi_pwm_tee;
		irq_trigger_type = "IRQF_TRIGGER_LOW";
		//power_on-gpios = <&gpio       GPIOM_6       GPIO_ACTIVE_HIGH>;
		//interrupt-gpios = <&gpio       GPIOM_7       GPIO_ACTIVE_HIGH>;
		pwm_channel1_conf {
			pwms = <&pwm_n 0 30541 0>;
			duty-cycle = <15270>;
			times = <40>;
		};
		pwm_channel2_conf {
			pwms = <&pwm_n 1 30600 0>;
			duty-cycle = <15300>;
			times = <10>;
		};
	};

	rtc: rtc@fe430000 {
		compatible = "amlogic,meson-rtc";
		reg = <0xfe430000 0x38>;
		interrupts = <GIC_SPI 201 IRQ_TYPE_EDGE_RISING>;
		time-storage-format-gray;
		clocks = <&ao_clkc CLKID_AO_OSCIN32K_CLK>,
			 <&ao_clkc CLKID_AO_SYS_RTC_DIG>;
		clock-names = "osc", "sys";
		status = "okay";
		assigned-clocks = <&ao_clkc CLKID_AO_OSCIN32K_CLK>;
		assigned-clock-parents = <&xtal_32k>;
	};
	jpegenc {
		compatible = "amlogic, jpegenc";
		dev_name = "jpegenc";
		status = "okay";
		power-domains = <&pwrdm PDID_C4_HCODEC>;
		clocks = <&clkc CLKID_SYS_DOS
			&clkc CLKID_HCODEC>;
		clock-names = "clk_dos",
			"clk_jpeg_enc";
		interrupts = <GIC_SPI 96 IRQ_TYPE_EDGE_RISING>;
		interrupt-names = "mailbox_0";
	};

	tahoe_enc {
		compatible = "amlogic, tahoe";
		dev_name = "tahoe";
		status = "okay";
		reg = <0xfe310000 0x400000>;
		power-domains = <&pwrdm PDID_C4_TAHOE>;
		clocks = <&clkc CLKID_SYS_TAHOE
			   &clkc CLKID_TAHOE>;
		clock-names = "clk_tahoe_dos",
			   "clk_tahoe_enc";
		interrupts = <0x00 0x86 0x01>,
				<0x00 0x5c 0x01>,
				<0x00 0x5d 0x01>,
				<0x00 0x5e 0x01>,
				<0x00 0x5f 0x01>,
				<0x00 0x87 0x01>, //4
				<0x00 0x88 0x01>,
				<0x00 0x89 0x01>,
				<0x00 0x8a 0x01>,
				<0x00 0x8b 0x01>,
				<0x00 0x8c 0x01>,
				<0x00 0x8d 0x01>,
				<0x00 0x8e 0x01>,
				<0x00 0xcc 0x01>,//12
				<0x00 0xcd 0x01>,
				<0x00 0xce 0x01>,
				<0x00 0xcf 0x01>,
				<0x00 0xd0 0x01>,
				<0x00 0xd1 0x01>,
				<0x00 0xd2 0x01>,
				<0x00 0xd3 0x01>,
				<0x00 0xd4 0x01>,
				<0x00 0xd5 0x01>;
		interrupt-names = "tahoe_irq0",
				"tahoe_sp_irq0",
				"tahoe_sp_irq1",
				"tahoe_sp_irq2",
				"tahoe_sp_irq3",
				"tahoe_sp_irq4",
				"tahoe_sp_irq5",
				"tahoe_sp_irq6",
				"tahoe_sp_irq7",
				"tahoe_sp_irq8",
				"tahoe_sp_irq9",
				"tahoe_sp_irq10",
				"tahoe_sp_irq11",
				"tahoe_sp_irq12",
				"tahoe_sp_irq13",
				"tahoe_sp_irq14",
				"tahoe_sp_irq15",
				"tahoe_sp_irq16",
				"tahoe_sp_irq17",
				"tahoe_sp_irq18",
				"tahoe_sp_irq19",
				"tahoe_sp_irq20",
				"tahoe_sp_irq21";
	};

	cve:mbd_cve {
		compatible = "amlogic, cve";
		reg = <0xFE046000 0x800>;
		reg-names = "cve";
		interrupts = <GIC_SPI 133 IRQ_TYPE_EDGE_RISING>;
		interrupt-names = "cve";
		clocks = <&clkc CLKID_CVE>, <&clkc CLKID_CVE_ARB>, <&clkc CLKID_SYS_CVE>;
		clock-names = "clk_cve", "clk_cve_arb", "clk_sys_cve";
		//clk-rate = <666000000>;
		power-domains = <&pwrdm PDID_C4_CVE>;
		status = "okay";
	};

	ge2d {
		compatible = "amlogic, mbp-ge2d-c4";
		status = "okay";
		interrupts = <GIC_SPI 217 IRQ_TYPE_EDGE_RISING>;
		interrupt-names = "ge2d";
		clocks = <&clkc CLKID_GE2D>, <&clkc CLKID_CVE_ARB>;
		clock-names = "clk_ge2d_gate", "cve_arb";
		reg = <0xfe04c000 0x2000>;
		power-domains = <&pwrdm PDID_C4_GE2D>;
	};

	mbd_audio: mbd_audio {
		compatible = "amlogic, mbd_audio_c4";
		status = "disabled";
		#address-cells=<1>;
		#size-cells=<1>;
		ranges;

		power-domains = <&pwrdm PDID_C4_AUDIO_TOP>;
		clocks = <&clkc CLKID_HIFI_PLL>;
		clock-names = "clk_srcpll";

		interrupts = <
			GIC_SPI 32 IRQ_TYPE_EDGE_RISING
			GIC_SPI 33 IRQ_TYPE_EDGE_RISING
			GIC_SPI 36 IRQ_TYPE_EDGE_RISING
			GIC_SPI 37 IRQ_TYPE_EDGE_RISING
			GIC_SPI 38 IRQ_TYPE_EDGE_RISING
			>;
		interrupt-names =
			"toddr_a", "toddr_b",
			"frddr_a", "frddr_b", "frddr_c";
		diff_output = <1>;
		//Source of the input data of DACL and DACR:
		//0 = The left channel data of I2S_DIN to left channel,
		//	The right channel data of I2S_DIN to right channel.
		//1 = The left channel data of I2S_DIN to right channel,
		//	The right channel data of I2S_DIN to left channel.
		acodec_LR_swap = <1>;
		pdm_bus {
			reg = <0xFE422000 0x400>;
		};
		audiobus_base {
			reg = <0xFE420000 0x1000>;
		};
		vad_top_base {
			reg = <0xFE421000 0x400>;
		};
		acodec_base {
			reg = <0xFE01A000 0x6c>;
		};
	};

	amlgdc {
		#address-cells=<2>;
		#size-cells=<2>;
		status = "okay";
		compatible = "amlogic, mbp-dewarp-v2";
		reg = <0xfe047c00 0x000015c>;
		interrupts = <GIC_SPI 143 IRQ_TYPE_EDGE_RISING
				GIC_SPI 150 IRQ_TYPE_EDGE_RISING>;
		interrupt-names = "gdc_done", "opp_done";
		clocks = <&clkc CLKID_DEWARP>, <&clkc CLKID_CVE_ARB>, <&clkc CLKID_ISP>;
		clock-names = "clk_gate", "cve_arb", "isp_clk";
		clk-rate = <800000000>;
	};

	freertos: freertos {
		compatible = "amlogic,freertos";
		status = "disabled";
		irqs_rsv = <32 177>;
	};

	aml_dma: aml_dma@fe440400 {
		compatible = "amlogic,aml_p1_dma";
		reg = <0xfe440400 0x48>;
		interrupts = <GIC_SPI 24 IRQ_TYPE_EDGE_RISING>;
		aml_aes {
				compatible = "amlogic,aes_g12a_dma";
				dev_name = "aml_aes_dma";
				status = "okay";
				iv_swap = /bits/ 8 <0x0>;
				/*power-domains = <&pwrdm PDID_CX_DMA>;*/
		};
		aml_sha {
				compatible = "amlogic,sha_dma";
				dev_name = "aml_sha_dma";
				status = "okay";
				hw_ctx_sz = /bits/ 32 <0x28>;
				/*power-domains = <&pwrdm PDID_CX_DMA>;*/
		};
		aml_tdes {
				compatible = "amlogic,des_dma,tdes_dma";
				dev_name = "aml_tdes_dma";
				status = "okay";
				/*power-domains = <&pwrdm PDID_CX_DMA>;*/
		};
		crypto {
				compatible = "amlogic,crypto_sc2";
				dev_name = "aml_crypto_dev";
				status = "okay";
				// Use thread 1.
				// Since there is no bl31 running on c4, no chance
				// to set thread 5 to DMA SEC register.
				thread = /bits/ 8 <0x1>;
				// Adjust IRQ number to 25 for thread 1.
				interrupts = <0 25 1>;
				/*power-domains = <&pwrdm PDID_CX_DMA>;*/
		};
	};

	rng{
		compatible="amlogic,meson-rng";
		status="okay";
		#address-cells = <1>;
		#size-cells = <1>;
		reg = <0xfe440788 0x0c>;
		quality=/bits/ 16 <1000>;
		version = <2>;
	};

	chosen {
		bootargs = "usbcore.autosuspend=-1 dm_mod.reserved_bio_based_ios=8";
	};

	aml_mkl {
		compatible = "amlogic,aml_mkl";
		reg = <0xfe440200 0xf0>;
		kl_type = <1>;
		kl_vid_type = <0>;
		kl_offset = <0x80 0x88 0x8c 0x90>;
		status = "okay";
	};

	aml_kt {
		compatible = "amlogic,aml_kt";
		reg = <0xfe440500 0xa0>;
		kt_offset = <0x80 0x88 0x8c 0x90 0x94 0x98 0x9c>;
		kt_cap = <0x2007 0x3f 0 16 0 32>;
		kt_reserved = <0>;
		kt_host_key_max_len = <32>;
		status = "okay";
	};

	jtag {
		compatible = "amlogic, jtag";
		status = "okay";
		select = "disable"; /* disable/jtag_a/jtag_b */
		pinctrl-names="jtag_a_pins", "jtag_b_pins";
		pinctrl-0=<&jtag_a_pins>;
		pinctrl-1=<&jtag_b_pins>;
	};
};

/* add pin mux here */
&periphs_pinctrl {
	i2c0_master_pins1:i2c0_pins1 {
		mux {
			groups = "i2cm_a_scl",
				"i2cm_a_sda";
			function = "i2c0";
			bias-disable;
			drive-strength-microamp = <3000>;
		};
	};

	i2c0_master_sleep_pins1:i2c0_sleep_pins1 {
		mux {
			groups = "GPIOD_0", "GPIOD_1";
			function = "gpio_periphs";
			input-enable;
		};
	};

	i2c0_master_pins2:i2c0_pins2 {
		mux {
			groups = "i2cm_a_scl_e",
				"i2cm_a_sda_e";
			function = "i2c0";
			bias-disable;
			drive-strength-microamp = <3000>;
		};
	};

	i2c0_master_sleep_pins2:i2c0_sleep_pins2 {
		mux {
			groups = "GPIOE_0", "GPIOE_1";
			function = "gpio_periphs";
			input-enable;
		};
	};

	i2c1_master_pins1:i2c1_pins1 {
		mux {
			groups = "i2cm_b_scl",
				"i2cm_b_sda";
			function = "i2c1";
			bias-disable;
			drive-strength-microamp = <3000>;
		};
	};

	i2c1_master_sleep_pins1:i2c1_sleep_pins1 {
		mux {
			groups = "GPIOD_2", "GPIOD_3";
			function = "gpio_periphs";
			input-enable;
		};
	};

	i2c1_master_pins2:i2c1_pins2 {
		mux {
			groups = "i2cm_b_sda_b",
				"i2cm_b_scl_b";
			function = "i2c1";
			bias-disable;
			drive-strength-microamp = <3000>;
		};
	};

	i2c1_master_sleep_pins2:i2c1_sleep_pins2 {
		mux {
			groups = "GPIOB_11", "GPIOB_12";
			function = "gpio_periphs";
			input-enable;
		};
	};

	i2c1_master_pins3:i2c1_pins3 {
		mux {
			groups = "i2c1_sda_b",
				"i2c1_scl_b13";
			function = "i2c1";
			bias-disable;
			drive-strength-microamp = <3000>;
		};
	};

	i2c1_master_sleep_pins3:i2c1_sleep_pins3 {
		mux {
			groups = "GPIOB_11", "GPIOB_13";
			function = "gpio_periphs";
			input-enable;
		};
	};

	i2c1_master_pins4:i2c1_pins4 {
		mux {
			groups = "i2cm_b_sda_m",
				"i2cm_b_scl_m";
			function = "i2c1";
			bias-disable;
			drive-strength-microamp = <3000>;
		};
	};

	i2c1_master_sleep_pins4:i2c1_sleep_pins4 {
		mux {
			groups = "GPIOM_6", "GPIOM_7";
			function = "gpio_periphs";
			input-enable;
		};
	};

	i2c1_master_pins5:i2c1_pins5 {
		mux {
			groups = "i2cm_b_sda_m1",
				"i2cm_b_scl_m0";
			function = "i2c1";
			bias-disable;
			drive-strength-microamp = <3000>;
		};
	};

	i2c1_master_sleep_pins5:i2c1_sleep_pins5 {
		mux {
			groups = "GPIOM_0", "GPIOM_1";
			function = "gpio_periphs";
			input-enable;
		};
	};

	i2c2_master_pins1:i2c2_pins1 {
		mux {
			groups = "i2cm_c_sda",
				"i2cm_c_scl";
			function = "i2c2";
			bias-disable;
			drive-strength-microamp = <3000>;
		};
	};

	i2c2_master_sleep_pins1:i2c2_sleep_pins1 {
		mux {
			groups = "GPIOE_2", "GPIOE_3";
			function = "gpio_periphs";
			input-enable;
		};
	};

	i2c3_master_pins1:i2c3_pins1 {
		mux {
			groups = "i2cm_d_sda",
				"i2cm_d_scl";
			function = "i2c3";
			bias-disable;
			drive-strength-microamp = <3000>;
		};
	};

	i2c3_master_sleep_pins1:i2c3_sleep_pins1 {
		mux {
			groups = "GPIOD_4", "GPIOD_5";
			function = "gpio_periphs";
			input-enable;
		};
	};

	i2c3_master_pins2:i2c3_pins2 {
		mux {
			groups = "i2cm_d_sda_b",
				"i2cm_d_scl_b";
			function = "i2c3";
			bias-disable;
			drive-strength-microamp = <3000>;
		};
	};

	i2c3_master_sleep_pins2:i2c3_sleep_pins2 {
		mux {
			groups = "GPIOB_8", "GPIOB_9";
			function = "gpio_periphs";
			input-enable;
		};
	};

	i2c3_master_pins3:i2c3_pins3 {
		mux {
			groups = "i2cm_d_sda_c",
				"i2cm_d_scl_c";
			function = "i2c3";
			bias-disable;
			drive-strength-microamp = <3000>;
		};
	};

	i2c3_master_sleep_pins3:i2c3_sleep_pins3 {
		mux {
			groups = "GPIOC_4", "GPIOC_5";
			function = "gpio_periphs";
			input-enable;
		};
	};

	i2c3_master_pins4:i2c3_pins4 {
		mux {
			groups = "i2cm_d_scl_x",
				"i2cm_d_sda_x";
			function = "i2c3";
			bias-disable;
			drive-strength-microamp = <3000>;
		};
	};

	i2c3_master_sleep_pins4:i2c3_sleep_pins4 {
		mux {
			groups = "GPIOX_4", "GPIOX_5";
			function = "gpio_periphs";
			input-enable;
		};
	};

	i2c3_master_pins5:i2c3_pins5 {
		mux {
			groups = "i2cm_d_sda_m",
				"i2cm_d_scl_m";
			function = "i2c3";
			bias-disable;
			drive-strength-microamp = <3000>;
		};
	};

	i2c3_master_sleep_pins5:i2c3_sleep_pins5 {
		mux {
			groups = "GPIOM_4", "GPIOM_5";
			function = "gpio_periphs";
			input-enable;
		};
	};

	i2c4_master_pins1:i2c4_pins1 {
		mux {
			groups = "i2cs_a_sda",
				"i2cs_a_scl";
			function = "i2c_slave";
			bias-disable;
			drive-strength-microamp = <3000>;
		};
	};

	i2c4_master_sleep_pins1:i2c4_sleep_pins1 {
		mux {
			groups = "GPIOD_0", "GPIOD_1";
			function = "gpio_periphs";
			input-enable;
		};
	};

	i2c4_master_pins2:i2c4_pins2 {
		mux {
			groups = "i2cs_a_sda_b",
				"i2cs_a_scl_b";
			function = "i2c_slave";
			bias-disable;
			drive-strength-microamp = <3000>;
		};
	};

	i2c4_master_sleep_pins2:i2c4_sleep_pins2 {
		mux {
			groups = "GPIOB_8", "GPIOB_9";
			function = "gpio_periphs";
			input-enable;
		};
	};

	a_uart_pins1:a_uart1 {
		mux {
			groups = "uart_a_tx_b",
				"uart_a_rx_b";
			function = "uart_a";
			bias-pull-up;
			drive-strength-microamp = <3000>;
		};
	};

	a_uart_pins2:a_uart2 {
		mux {
			groups = "uart_a_tx_c",
				"uart_a_rx_c";
			function = "uart_a";
			bias-pull-up;
			drive-strength-microamp = <3000>;
		};
	};

	a_uart_pins3:a_uart3 {
		mux {
			groups = "uart_a_tx",
				"uart_a_rx";
			function = "uart_a";
			bias-pull-up;
			drive-strength-microamp = <3000>;
		};
	};

	a_uart_pins4:a_uart4 {
		mux {
			groups = "uart_a_tx_x",
				"uart_a_rx_x";
			function = "uart_a";
			bias-pull-up;
			drive-strength-microamp = <3000>;
		};
	};

	a_uart_pins5:a_uart5 {
		mux {
			groups = "uart_a_tx_m",
				"uart_a_rx_m";
			function = "uart_a";
			bias-pull-up;
			drive-strength-microamp = <3000>;
		};
	};

	b_uart_pins1:b_uart1 {
		mux {
			groups = "uart_b_tx",
				"uart_b_rx";
			function = "uart_b";
			bias-pull-up;
			drive-strength-microamp = <3000>;
		};
	};

	b_uart_pins2:b_uart2 {
		mux {
			groups = "uart_b_tx_a",
				"uart_b_rx_a";
			function = "uart_b";
			bias-pull-up;
			drive-strength-microamp = <3000>;
		};
	};

	c_uart_pins1:c_uart1 {
		mux {
			groups = "uart_c_tx_c",
				"uart_c_rx_c";
			function = "uart_c";
			bias-pull-up;
			drive-strength-microamp = <3000>;
		};
	};

	c_uart_pins2:c_uart2 {
		mux {
			groups = "uart_c_tx_x",
				"uart_c_rx_x";
			function = "uart_c";
			bias-pull-up;
			drive-strength-microamp = <3000>;
		};
	};

	c_uart_pins3:c_uart3 {
		mux {
			groups = "uart_c_tx",
				"uart_c_rx";
			function = "uart_c";
			bias-pull-up;
			drive-strength-microamp = <3000>;
		};
	};

	c_uart_pins4:c_uart4 {
		mux {
			groups = "uart_c_tx_m",
				"uart_c_rx_m";
			function = "uart_c";
			bias-pull-up;
			drive-strength-microamp = <3000>;
		};
	};

	c_uart_pins5:c_uart5 {
		mux {
			groups = "uart_c_tx_m2",
				"uart_c_rx_m3",
				"uart_c_cts_m4",
				"uart_c_rts_m5";
			function = "uart_c";
			bias-pull-up;
			drive-strength-microamp = <3000>;
		};
	};

	c_uart_pins6:c_uart6 {
		mux {
			groups = "uart_c_tx_b",
				"uart_c_rx_b";
			function = "uart_c";
			bias-pull-up;
			drive-strength-microamp = <3000>;
		};
	};

	e_uart_pins1:e_uart1 {
		mux {
			groups = "uart_e_tx",
				"uart_e_rx",
				"uart_e_rts",
				"uart_e_cts";
			function = "uart_e";
			bias-pull-up;
			drive-strength-microamp = <3000>;
		};
	};

	f_uart_pins1:f_uart1 {
		mux {
			groups = "uart_f_tx",
				"uart_f_rx";
			function = "uart_f";
			bias-pull-up;
			drive-strength-microamp = <3000>;
		};
	};

	jtag_a_pins:jtag_a_pin {
		mux {
			groups = "jtag_a_clk",
			"jtag_a_tms",
			"jtag_a_tdi",
			"jtag_a_tdo";
			function = "jtag_a";
		};
	};

	jtag_b_pins:jtag_b_pin {
		mux {
			groups = "jtag_b_clk",
			"jtag_b_tms",
			"jtag_b_tdi",
			"jtag_b_tdo";
			function = "jtag_b";
		};
	};

	remote_pins:remote_pin {
		mux {
			groups = "ir_in_d0";
			function = "ir_in";
		};
	};

	emmc_pins: emmc {
		mux {
			groups = "emmc_d0",
				 "emmc_d1",
				 "emmc_d2",
				 "emmc_d3",
				 "emmc_d4",
				 "emmc_d5",
				 "emmc_d6",
				 "emmc_d7",
				 "emmc_clk",
				 "emmc_cmd";
			function = "emmc";
			bias-pull-up;
			input-enable;
			drive-strength-microamp = <3000>;
		};
		mux1 {
			groups = "emmc_ds";
			function = "emmc";
			input-enable;
			bias-pull-down;
			drive-strength-microamp = <3000>;
		};
		mux2 {
			groups = "emmc_reset";
			function = "emmc";
			bias-pull-up;
			drive-strength-microamp = <3000>;
		};
	};

	emmc_pins_sleep:emmc_all_pins_sleep {
		mux {
			groups = "GPIOB_0",
				 "GPIOB_1",
				 "GPIOB_2",
				 "GPIOB_3",
				 "GPIOB_4",
				 "GPIOB_5",
				 "GPIOB_6",
				 "GPIOB_7",
				 "GPIOB_8",
				 "GPIOB_10";
			function = "gpio_periphs";
			input-enable;
		};
		mux1 {
			groups = "GPIOB_11";
			function = "gpio_periphs";
			input-enable;
		};
	};

	emmc_clk_gate_pins: emmc_clk_gate {
		mux {
			groups = "emmc_clk";
			function = "emmc";
			bias-pull-down;
			drive-strength-microamp = <3000>;
		};
	};

	sdio_x_clk_gate_pins:sdio_x_clk_cmd_pins {
		mux {
			groups = "sdio_clk";
			function = "sdio";
			bias-pull-down;
			drive-strength-microamp = <3000>;
		};
	};

	sdio_x_pins:sdio_x_all_pins {
		mux {
			groups = "sdio_d0",
				 "sdio_d1",
				 "sdio_d2",
				 "sdio_d3",
				 "sdio_clk",
				 "sdio_cmd";
			function = "sdio";
			input-enable;
			bias-pull-up;
			drive-strength-microamp = <3000>;
		};
	};

	sdio_m_clk_gate_pins:sdio_m_clk_cmd_pins {
		mux {
			groups = "sdio_clk";
			function = "sdio";
			bias-pull-down;
			drive-strength-microamp = <3000>;
		};
	};

	sdio_m_pins:sdio_m_all_pins {
		mux {
			groups = "sdio_d0",
				 "sdio_d1",
				 "sdio_d2",
				 "sdio_d3",
				 "sdio_clk",
				 "sdio_cmd";
			function = "sdio";
			input-enable;
			bias-pull-up;
			drive-strength-microamp = <3000>;
		};
	};

	sdcard_pins:sdcard_all_pins {
		mux {
			groups = "sdcard_d0",
				 "sdcard_d1",
				 "sdcard_d2",
				 "sdcard_d3",
				 "sdcard_clk",
				 "sdcard_cmd";
			function = "sdcard";
			input-enable;
			bias-pull-up;
			drive-strength-microamp = <3000>;
		};
	};

	sdcard_clk_gate_pins:sdcard_clk_cmd_pins {
		mux {
			groups = "sdcard_clk";
			function = "sdcard";
			bias-pull-down;
			drive-strength-microamp = <3000>;
		};
	};

	sd_1bit_pins:sd_1bit_pins {
		mux {
			groups = "sdcard_d0",
				 "sdcard_cmd";
			function = "sdcard";
			input-enable;
			bias-pull-up;
			drive-strength-microamp = <3000>;
		};
		mux1 {
			groups = "sdcard_clk";
			function = "sdcard";
			bias-pull-up;
			output-high;
			drive-strength-microamp = <3000>;
		};
	};

	ao_to_sd_uart_pins:ao_to_sd_uart_pins {
		mux {
			groups = "uart_b_tx_c",
				 "uart_b_rx_c";
			function = "uart_b";
			bias-pull-up;
			input-enable;
		};
	};

	sdcard_pins_sleep:sdcard_all_pins_sleep {
		mux {
			groups = "GPIOC_0",
				 "GPIOC_1",
				 "GPIOC_2",
				 "GPIOC_3",
				 "GPIOC_4",
				 "GPIOC_5";
			function = "gpio_periphs";
			output-low;
			bias-disable;
		};
	};

	all_nand_pins: all_nand_pins {
		mux {
			groups = "emmc_d0",
				"emmc_d1",
				"emmc_d2",
				"emmc_d3",
				"emmc_d4",
				"emmc_d5",
				"emmc_d6",
				"emmc_d7",
				"nand_ce0",
				"nand_ale",
				"nand_cle",
				"nand_wen_clk",
				"nand_ren_wr";
			function = "nand";
			input-enable;
			drive-strength-microamp = <4000>;
		};
	};

	nand_cs_pins: nand_cs {
		mux {
			groups = "nand_ce0";
			function = "nand";
		};
	};

	irblaster_pins:irblaster_pin {
		mux {
			groups = "ir_out";
			function = "ir_out";
		};
	};

	pwm_a_pins1: pwm_a_pins1 {
		mux {
			groups = "pwm_a";
			function = "pwm_a";
		};
	};

	pwm_b_pins1: pwm_b_pins1 {
		mux {
			groups = "pwm_b";
			function = "pwm_b";
		};
	};

	pwm_c_pins1: pwm_c_pins1 {
		mux {
			groups = "pwm_c";
			function = "pwm_c";
		};
	};

	pwm_d_pins1: pwm_d_pins1 {
		mux {
			groups = "pwm_d";
			function = "pwm_d";
		};
	};

	pwm_e_pins1: pwm_e_pins1 {
		mux {
			groups = "pwm_e";
			function = "pwm_e";
		};
	};

	pwm_f_pins1: pwm_f_pins1 {
		mux {
			groups = "pwm_f";
			function = "pwm_f";
		};
	};

	pwm_f_pins2: pwm_f_pins2 {
		mux {
			groups = "pwm_f_b";
			function = "pwm_f";
		};
	};

	pwm_g_pins1: pwm_g_pins1 {
		mux {
			groups = "pwm_g_b";
			function = "pwm_g";
		};
	};

	pwm_g_pins2: pwm_g_pins2 {
		mux {
			groups = "pwm_g_c";
			function = "pwm_g";
		};
	};

	pwm_g_pins3: pwm_g_pins3 {
		mux {
			groups = "pwm_g_b";
			function = "pwm_g";
		};
	};

	pwm_g_pins4: pwm_g_pins4 {
		mux {
			groups = "pwm_g_x";
			function = "pwm_g";
		};
	};

	pwm_h_pins1: pwm_h_pins1 {
		mux {
			groups = "pwm_h";
			function = "pwm_h";
		};
	};

	pwm_h_pins2: pwm_h_pins2 {
		mux {
			groups = "pwm_h_b";
			function = "pwm_h";
		};
	};

	pwm_h_pins3: pwm_h_pins3 {
		mux {
			groups = "pwm_h_c";
			function = "pwm_h";
		};
	};

	pwm_h_pins4: pwm_h_pins4 {
		mux {
			groups = "pwm_h_x";
			function = "pwm_h";
		};
	};

	pwm_i_pins1: pwm_i_pins1 {
		mux {
			groups = "pwm_i";
			function = "pwm_i";
		};
	};

	pwm_i_pins2: pwm_i_pins2 {
		mux {
			groups = "pwm_i_c";
			function = "pwm_i";
		};
	};

	pwm_i_pins3: pwm_i_pins3 {
		mux {
			groups = "pwm_i_m";
			function = "pwm_i";
		};
	};

	pwm_i_pins4: pwm_i_pins4 {
		mux {
			groups = "pwm_i_x";
			function = "pwm_i";
		};
	};

	pwm_j_pins1: pwm_j_pins1 {
		mux {
			groups = "pwm_j";
			function = "pwm_j";
		};
	};

	pwm_j_pins2: pwm_j_pins2 {
		mux {
			groups = "pwm_j_a";
			function = "pwm_j";
		};
	};

	pwm_j_pins3: pwm_j_pins3 {
		mux {
			groups = "pwm_j_c";
			function = "pwm_j";
		};
	};

	pwm_j_pins4: pwm_j_pins4 {
		mux {
			groups = "pwm_j_m";
			function = "pwm_j";
		};
	};

	pwm_j_pins4: pwm_j_pins4 {
		mux {
			groups = "pwm_j_x";
			function = "pwm_j";
		};
	};

	pwm_j_pins5: pwm_j_pins5 {
		mux {
			groups = "pwm_j_x3";
			function = "pwm_j";
		};
	};

	pwm_k_pins1: pwm_k_pins1 {
		mux {
			groups = "pwm_k";
			function = "pwm_k";
		};
	};

	pwm_k_pins2: pwm_k_pins2 {
		mux {
			groups = "pwm_k_b";
			function = "pwm_k";
		};
	};

	pwm_k_pins3: pwm_k_pins3 {
		mux {
			groups = "pwm_k_c";
			function = "pwm_k";
		};
	};

	pwm_k_pins4: pwm_k_pins4 {
		mux {
			groups = "pwm_k_m";
			function = "pwm_k";
		};
	};

	pwm_k_pins5: pwm_k_pins5 {
		mux {
			groups = "pwm_k_x";
			function = "pwm_k";
		};
	};

	pwm_k_pins6: pwm_k_pins6 {
		mux {
			groups = "pwm_k_x4";
			function = "pwm_k";
		};
	};

	pwm_l_pins1: pwm_l_pins1 {
		mux {
			groups = "pwm_l";
			function = "pwm_l";
		};
	};

	pwm_l_pins2: pwm_l_pins2 {
		mux {
			groups = "pwm_l_c";
			function = "pwm_l";
		};
	};

	pwm_l_pins3: pwm_l_pins3 {
		mux {
			groups = "pwm_l_x";
			function = "pwm_l";
		};
	};

	pwm_m_pins1: pwm_m_pins1 {
		mux {
			groups = "pwm_m";
			function = "pwm_m";
		};
	};

	pwm_m_pins2: pwm_m_pins2 {
		mux {
			groups = "pwm_m_a";
			function = "pwm_m";
		};
	};

	pwm_m_pins3: pwm_m_pins3 {
		mux {
			groups = "pwm_m_b";
			function = "pwm_m";
		};
	};

	pwm_m_pins4: pwm_m_pins4 {
		mux {
			groups = "pwm_m_c";
			function = "pwm_m";
		};
	};

	pwm_m_pins5: pwm_m_pins5 {
		mux {
			groups = "pwm_m_x";
			function = "pwm_m";
		};
	};

	pwm_n_pins1: pwm_n_pins1 {
		mux {
			groups = "pwm_n";
			function = "pwm_n";
		};
	};

	spinf_pins:spinf_pins {
		mux {
			groups = "spinf_mo_d0",
				"spinf_mi_d1",
				"spinf_wp_d2",
				"spinf_hold_d3",
				"spinf_clk",
				"spinf_cs0";
			function = "spinf";
			drive-strength-microamp = <3000>;
		};
	};

	spicc0_pins_b: spicc0_pins_b {
		mux {
			groups = "spi_a_mosi",
				 "spi_a_miso",
				 "spi_a_ss0",
				 //"spi_a_ss1",
				 //"spi_a_ss2",
				 "spi_a_sclk";
			function = "spi_a";
			drive-strength-microamp = <3000>;
		};
	};

	spicc0_pins_c: spicc0_pins_c {
		mux {
			groups = "spi_a_mosi_c",
				 "spi_a_miso_c",
				 "spi_a_ss0_c",
				 //"spi_a_ss1_c",
				 "spi_a_sclk_c";
			function = "spi_a";
			drive-strength-microamp = <3000>;
		};
	};

	spicc0_pins_x: spicc0_pins_x {
		mux {
			groups = "spi_a_mosi_x",
				 "spi_a_miso_x",
				 "spi_a_ss0_x",
				 //"spi_a_ss1_x",
				 //"spi_a_ss2_x",
				 "spi_a_sclk_x";
			function = "spi_a";
			drive-strength-microamp = <3000>;
		};
	};

	spicc0_pins_m: spicc0_pins_m {
		mux {
			groups = "spi_a_mosi_m5",
				 "spi_a_miso_m4",
				 //"spi_a_mosi_m",
				 //"spi_a_miso_m",
				 "spi_a_ss0_m",
				 "spi_a_sclk_m";
			function = "spi_a";
			drive-strength-microamp = <3000>;
		};
	};

	spicc0_pins_ao: spicc0_pins_ao {
		mux {
			groups = "spi_a_mosi_ao4",
				 "spi_a_miso_ao5",
				 "spi_a_ss0_ao7",
				 "spi_a_sclk_ao6";
			function = "spi_a";
			drive-strength-microamp = <3000>;
		};
	};

	spicc1_pins_d: spicc1_pins_d {
		mux {
			groups = "spi_b_mosi",
				 "spi_b_miso",
				 "spi_b_ss0",
				 "spi_b_ss1",
				 "spi_b_sclk";
			function = "spi_b";
			drive-strength-microamp = <3000>;
		};
	};

	spicc1_pins_x: spicc1_pins_x {
		mux {
			groups = "spi_b_mosi_x",
				 "spi_b_miso_x",
				 "spi_b_ss1_x",
				 "spi_b_sclk_x";
			function = "spi_b";
			drive-strength-microamp = <3000>;
		};
	};

	spicc1_pins_ao: spicc1_pins_ao {
		mux {
			groups = "spi_b_mosi_ao12",
				 "spi_b_miso_ao10",
				 "spi_b_ss0_ao13",
				 "spi_b_sclk_ao11";
			function = "spi_b";
			drive-strength-microamp = <3000>;
		};
	};
};

&analog_pinctrl {
	lcd_dsi_on_pins: lcd_dsi_on_pin {
		mux {
			groups = "dsi_clkp", "dsi_clkn",
				 "dsi_d0p", "dsi_d0n",
				 "dsi_d1p", "dsi_d1n",
				 "dsi_d2p", "dsi_d2n",
				 "dsi_d3p", "dsi_d3n";
			function = "dsi";
		};
	};
};

&aobus_pinctrl {

	pwm_b_ao_pins1: pwm_b_ao_pins1 {
		mux {
			groups = "pwm_b_ao";
			function = "pwm_b_ao";
		};
	};

	pwm_c_ao_pins1: pwm_c_ao_pins1 {
		mux {
			groups = "pwm_c_ao0";
			function = "pwm_c_ao";
		};
	};

	pwm_c_ao_pins2: pwm_c_ao_pins2 {
		mux {
			groups = "pwm_c_ao9";
			function = "pwm_c_ao";
		};
	};

	pwm_e_ao_pins1: pwm_e_ao_pins1 {
		mux {
			groups = "pwm_e_ao";
			function = "pwm_e_ao6";
		};
	};

	pwm_g_ao_pins1: pwm_g_ao_pins1 {
		mux {
			groups = "pwm_g_ao";
			function = "pwm_g_ao";
		};
	};

	pwm_h_ao_pins1: pwm_h_ao_pins1 {
		mux {
			groups = "pwm_h_ao";
			function = "pwm_h_ao";
		};
	};

	pwm_i_ao_pins1: pwm_i_ao_pins1 {
		mux {
			groups = "pwm_i_ao";
			function = "pwm_i_ao";
		};
	};

	pwm_ao_j_pins1: pwm_ao_j_pins1 {
		mux {
			groups = "pwm_j_ao";
			function = "pwm_j_ao";
		};
	};

	pwm_ao_j_pins2: pwm_ao_j_pins2 {
		mux {
			groups = "pwm_j_ao2";
			function = "pwm_j_ao";
		};
	};

	pwm_ao_k_pins1: pwm_ao_k_pins1 {
		mux {
			groups = "pwm_k_ao";
			function = "pwm_k_ao";
		};
	};

	pwm_ao_k_pins2: pwm_ao_k_pins2 {
		mux {
			groups = "pwm_k_ao_ao";
			function = "pwm_k_ao";
		};
	};

	pwm_l_ao_pins1: pwm_l_ao_pins1 {
		mux {
			groups = "pwm_l_ao";
			function = "pwm_l_ao";
		};
	};

	pwm_m_ao_pins1: pwm_m_ao_pins1 {
		mux {
			groups = "pwm_m_ao";
			function = "pwm_m_ao";
		};
	};

	pwm_n_ao_pins1: pwm_n_ao_pins1 {
		mux {
			groups = "pwm_n_ao3";
			function = "pwm_n_ao";
		};
	};

	pwm_n_ao_pins2: pwm_n_ao_pins2 {
		mux {
			groups = "pwm_n_ao10";
			function = "pwm_n_ao";
		};
	};

	i2c0_master_ao_pins1:i2c0_ao_pins1 {
		mux {
			groups = "i2cm_a_scl_ao0",
				"i2cm_a_sda_ao1";
			function = "i2c0";
			bias-disable;
			drive-strength-microamp = <3000>;
		};
	};

	i2c0_master_ao_sleep_pins1:i2c0_ao_sleep_pins1 {
		mux {
			groups = "GPIOAO_0", "GPIOAO_1";
			function = "gpio_periphs";
			input-enable;
		};
	};

	i2c1_master_ao_pins1:i2c1_ao_pins1 {
		mux {
			groups = "i2cm_b_scl_ao3",
				"i2cm_b_sda_ao2";
			function = "i2c1";
			bias-disable;
			drive-strength-microamp = <3000>;
		};
	};

	i2c1_master_ao_sleep_pins1:i2c1_ao_sleep_pins1 {
		mux {
			groups = "GPIOAO_2", "GPIOAO_3";
			function = "gpio_periphs";
			input-enable;
		};
	};

	i2c1_master_ao_pins2:i2c1_ao_pins2 {
		mux {
			groups = "i2cm_b_scl_ao11",
				"i2cm_b_sda_ao10";
			function = "i2c1";
			bias-disable;
			drive-strength-microamp = <3000>;
		};
	};

	i2c1_master_ao_sleep_pins2:i2c1_ao_sleep_pins2 {
		mux {
			groups = "GPIOAO_10", "GPIOAO_11";
			function = "gpio_periphs";
			input-enable;
		};
	};

	i2c2_master_ao_pins1:i2c2_ao_pins1 {
		mux {
			groups = "i2cm_c_scl_ao6",
				"i2cm_c_sda_ao7";
			function = "i2c2";
			bias-disable;
			drive-strength-microamp = <3000>;
		};
	};

	i2c2_master_ao_sleep_pins1:i2c2_ao_sleep_pins1 {
		mux {
			groups = "GPIOAO_6", "GPIOAO_7";
			function = "gpio_periphs";
			input-enable;
		};
	};

	d_uart_pins1:d_uart1 {
		mux {
			groups = "uart_d_rx",
				"uart_d_tx";
			function = "uart_d_ao";
			bias-pull-up;
			drive-strength-microamp = <3000>;
		};
	};

	e_uart_pins2:e_uart2 {
		mux {
			groups = "uart_e_rx_ao1",
				"uart_e_tx_ao0";
			function = "uart_e_ao";
			bias-pull-up;
			drive-strength-microamp = <3000>;
		};
	};

	e_uart_pins3:e_uart3 {
		mux {
			groups = "uart_e_rx_ao11",
				"uart_e_tx_ao10",
				"uart_e_cts_ao12",
				"uart_e_rts_ao13";
			function = "uart_e_ao";
			bias-pull-up;
			drive-strength-microamp = <3000>;
		};
	};

	f_uart_pins2:f_uart2 {
		mux {
			groups = "uart_f_rx_ao3",
				"uart_f_tx_ao2";
			function = "uart_f_ao";
			bias-pull-up;
			drive-strength-microamp = <3000>;
		};
	};
};

#include "mesonc4_cpufreq.dtsi"
